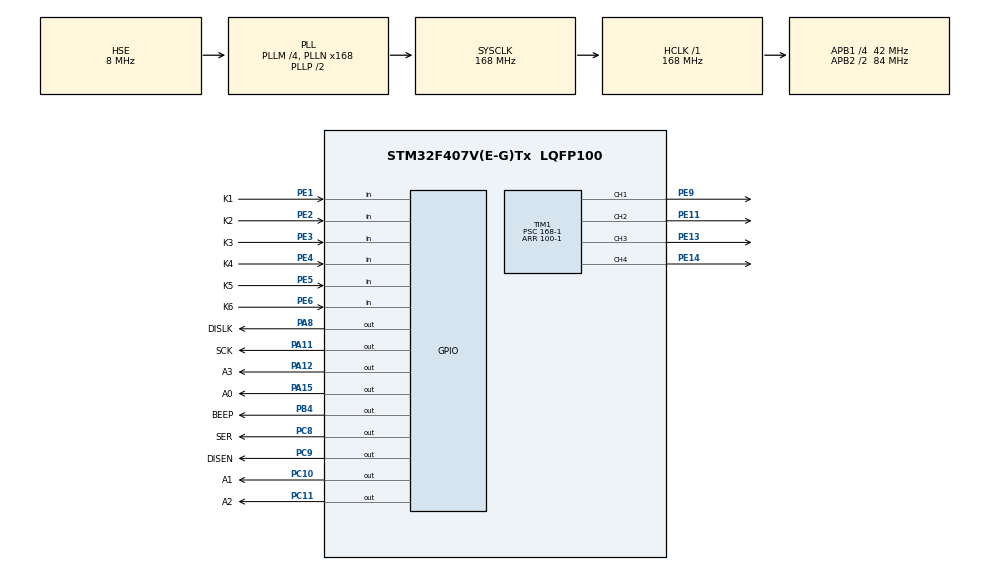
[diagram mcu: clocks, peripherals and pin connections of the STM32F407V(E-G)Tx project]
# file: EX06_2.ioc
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FREERTOS.Tasks01=TaskLED,24,256,StartTaskLED,Default,NULL,Dynamic,NULL,NULL;TaskBEEP,8,256,StartTaskBEEP,Default,NULL,Dynamic,NULL,NULL;TaskKEY,8,256,StartTaskKEY,Default,NULL,Dynamic,NULL,NULL;TaskSEG,8,128,StartTaskSEG,Default,NULL,Dynamic,NULL,NULL
Mcu.Family=STM32F4
Mcu.Name=STM32F407V(E-G)Tx
Mcu.Package=LQFP100
NVIC.PriorityGroup=NVIC_PRIORITYGROUP_4
NVIC.TIM1_BRK_TIM9_IRQn=true\:5\:0\:false\:false\:true\:true\:false\:true
NVIC.TIM4_IRQn=true\:5\:0\:false\:false\:true\:true\:true\:true
NVIC.TimeBase=TIM1_BRK_TIM9_IRQn
NVIC.TimeBaseIP=TIM9
PA11.GPIO_Label=SCK
PA11.Signal=GPIO_Output
PA12.GPIO_Label=A3
PA12.Signal=GPIO_Output
PA13.Mode=Serial_Wire
PA13.Signal=SYS_JTMS-SWDIO
PA14.Mode=Serial_Wire
PA14.Signal=SYS_JTCK-SWCLK
PA15.GPIO_Label=A0
PA15.Signal=GPIO_Output
PA8.GPIO_Label=DISLK
PA8.Signal=GPIO_Output
PB4.GPIO_Label=BEEP
PB4.Signal=GPIO_Output
PC10.GPIO_Label=A1
PC10.Signal=GPIO_Output
PC11.GPIO_Label=A2
PC11.Signal=GPIO_Output
PC8.GPIO_Label=SER
PC8.Signal=GPIO_Output
PC9.GPIO_Label=DISEN
PC9.Signal=GPIO_Output
PE1.GPIO_Label=K1
PE1.GPIO_PuPd=GPIO_PULLUP
PE1.Signal=GPIO_Input
PE11.Signal=S_TIM1_CH2
PE13.Signal=S_TIM1_CH3
PE14.Signal=S_TIM1_CH4
PE2.GPIO_Label=K2
PE2.GPIO_PuPd=GPIO_PULLUP
PE2.Signal=GPIO_Input
PE3.GPIO_Label=K3
PE3.GPIO_PuPd=GPIO_PULLUP
PE3.Signal=GPIO_Input
PE4.GPIO_Label=K4
PE4.GPIO_PuPd=GPIO_PULLUP
PE4.Signal=GPIO_Input
PE5.GPIO_Label=K5
PE5.GPIO_PuPd=GPIO_PULLDOWN
PE5.Signal=GPIO_Input
PE6.GPIO_Label=K6
PE6.GPIO_PuPd=GPIO_PULLDOWN
PE6.Signal=GPIO_Input
PE9.Signal=S_TIM1_CH1
PH0-OSC_IN.Mode=HSE-External-Oscillator
PH0-OSC_IN.Signal=RCC_OSC_IN
PH1-OSC_OUT.Mode=HSE-External-Oscillator
PH1-OSC_OUT.Signal=RCC_OSC_OUT
ProjectManager.HeapSize=0x200
ProjectManager.StackSize=0x400
ProjectManager.TargetToolchain=MDK-ARM V5.27
RCC.48MHZClocksFreq_Value=84000000
RCC.AHBFreq_Value=168000000
RCC.APB1CLKDivider=RCC_HCLK_DIV4
RCC.APB1Freq_Value=42000000
RCC.APB1TimFreq_Value=84000000
RCC.APB2CLKDivider=RCC_HCLK_DIV2
RCC.APB2Freq_Value=84000000
RCC.APB2TimFreq_Value=168000000
RCC.CortexFreq_Value=168000000
RCC.HCLKFreq_Value=168000000
RCC.HSE_VALUE=8000000
RCC.HSI_VALUE=16000000
RCC.LSE_VALUE=32768
RCC.PLLM=4
RCC.PLLN=168
RCC.PLLSourceVirtual=RCC_PLLSOURCE_HSE
RCC.SYSCLKFreq_VALUE=168000000
RCC.SYSCLKSource=RCC_SYSCLKSOURCE_PLLCLK
RCC.VCOOutputFreq_Value=336000000
SH.S_TIM1_CH1.0=TIM1_CH1,PWM Generation1 CH1
SH.S_TIM1_CH2.0=TIM1_CH2,PWM Generation2 CH2
SH.S_TIM1_CH3.0=TIM1_CH3,PWM Generation3 CH3
SH.S_TIM1_CH4.0=TIM1_CH4,PWM Generation4 CH4
TIM1.AutoReloadPreload=TIM_AUTORELOAD_PRELOAD_DISABLE
TIM1.Channel-PWM\ Generation1\ CH1=TIM_CHANNEL_1
TIM1.Channel-PWM\ Generation2\ CH2=TIM_CHANNEL_2
TIM1.Channel-PWM\ Generation3\ CH3=TIM_CHANNEL_3
TIM1.Channel-PWM\ Generation4\ CH4=TIM_CHANNEL_4
TIM1.OCIdleState_1=TIM_OCIDLESTATE_SET
TIM1.OCIdleState_2=TIM_OCIDLESTATE_SET
TIM1.OCIdleState_3=TIM_OCIDLESTATE_SET
TIM1.OCIdleState_4=TIM_OCIDLESTATE_SET
TIM1.OCPolarity_1=TIM_OCPOLARITY_LOW
TIM1.OCPolarity_2=TIM_OCPOLARITY_LOW
TIM1.OCPolarity_3=TIM_OCPOLARITY_LOW
TIM1.OCPolarity_4=TIM_OCPOLARITY_LOW
TIM1.Period=100-1
TIM1.Prescaler=168-1
TIM4.AutoReloadPreload=TIM_AUTORELOAD_PRELOAD_ENABLE
TIM4.Prescaler=168-1
VP_FREERTOS_VS_CMSIS_V2.Mode=CMSIS_V2
VP_SYS_VS_tim9.Mode=TIM9
VP_TIM1_VS_ClockSourceINT.Mode=Internal
VP_TIM4_VS_ClockSourceINT.Mode=Internal
board=custom

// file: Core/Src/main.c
/* USER CODE BEGIN Header */
/**
  ******************************************************************************
  * @file           : main.c
  * @brief          : Main program body
  ******************************************************************************
  * @attention
  *
  * <h2><center>&copy; Copyright (c) 2021 STMicroelectronics.
  * All rights reserved.</center></h2>
  *
  * This software component is licensed by ST under BSD 3-Clause license,
  * the "License"; You may not use this file except in compliance with the
  * License. You may obtain a copy of the License at:
  *                        opensource.org/licenses/BSD-3-Clause
  *
  ******************************************************************************
  */
/* USER CODE END Header */
#include "main.h"
#include "cmsis_os.h"
#include "tim.h"
#include "gpio.h"

/* USER CODE BEGIN PV */
int g_beep_time = 0;//Ĭ�ϲ���

/* USER CODE END PV */

void SystemClock_Config(void);
void MX_FREERTOS_Init(void);

int main(void)
{

  /* MCU Configuration--------------------------------------------------------*/

  /* Reset of all peripherals, Initializes the Flash interface and the Systick. */
  HAL_Init();

  /* Configure the system clock */
  SystemClock_Config();

  /* Initialize all configured peripherals */
  MX_GPIO_Init();
  MX_TIM4_Init();
  MX_TIM1_Init();

  /* Init scheduler */
  osKernelInitialize();  /* Call init function for freertos objects (in freertos.c) */
  MX_FREERTOS_Init();
  /* Start scheduler */
  osKernelStart();

  /* We should never get here as control is now taken by the scheduler */
  /* Infinite loop */
  while (1)
  {

  }
}

void SystemClock_Config(void)
{
  RCC_OscInitTypeDef RCC_OscInitStruct = {0};
  RCC_ClkInitTypeDef RCC_ClkInitStruct = {0};

  /** Configure the main internal regulator output voltage
  */
  __HAL_RCC_PWR_CLK_ENABLE();
  __HAL_PWR_VOLTAGESCALING_CONFIG(PWR_REGULATOR_VOLTAGE_SCALE1);
  /** Initializes the RCC Oscillators according to the specified parameters
  * in the RCC_OscInitTypeDef structure.
  */
  RCC_OscInitStruct.OscillatorType = RCC_OSCILLATORTYPE_HSE;
  RCC_OscInitStruct.HSEState = RCC_HSE_ON;
  RCC_OscInitStruct.PLL.PLLState = RCC_PLL_ON;
  RCC_OscInitStruct.PLL.PLLSource = RCC_PLLSOURCE_HSE;
  RCC_OscInitStruct.PLL.PLLM = 4;
  RCC_OscInitStruct.PLL.PLLN = 168;
  RCC_OscInitStruct.PLL.PLLP = RCC_PLLP_DIV2;
  RCC_OscInitStruct.PLL.PLLQ = 4;
  if (HAL_RCC_OscConfig(&RCC_OscInitStruct) != HAL_OK)
  {
    Error_Handler();
  }
  /** Initializes the CPU, AHB and APB buses clocks
  */
  RCC_ClkInitStruct.ClockType = RCC_CLOCKTYPE_HCLK|RCC_CLOCKTYPE_SYSCLK
                              |RCC_CLOCKTYPE_PCLK1|RCC_CLOCKTYPE_PCLK2;
  RCC_ClkInitStruct.SYSCLKSource = RCC_SYSCLKSOURCE_PLLCLK;
  RCC_ClkInitStruct.AHBCLKDivider = RCC_SYSCLK_DIV1;
  RCC_ClkInitStruct.APB1CLKDivider = RCC_HCLK_DIV4;
  RCC_ClkInitStruct.APB2CLKDivider = RCC_HCLK_DIV2;

  if (HAL_RCC_ClockConfig(&RCC_ClkInitStruct, FLASH_LATENCY_5) != HAL_OK)
  {
    Error_Handler();
  }
}

 /**
  * @brief  Period elapsed callback in non blocking mode
  * @note   This function is called  when TIM9 interrupt took place, inside
  * HAL_TIM_IRQHandler(). It makes a direct call to HAL_IncTick() to increment
  * a global variable "uwTick" used as application time base.
  * @param  htim : TIM handle
  * @retval None
  */
void HAL_TIM_PeriodElapsedCallback(TIM_HandleTypeDef *htim)
{
  /* USER CODE BEGIN Callback 0 */
	static uint8_t led_count=0;
  /* USER CODE END Callback 0 */
  if (htim->Instance == TIM9) {
    HAL_IncTick();
  }
  /* USER CODE BEGIN Callback 1 */
	if(htim->Instance == TIM4)
	{
		if(g_beep_time>0)
		{
			HAL_GPIO_TogglePin(BEEP_GPIO_Port,BEEP_Pin);
			--g_beep_time;
		}
	}

  /* USER CODE END Callback 1 */
}

void Error_Handler(void)
{
  __disable_irq();
  while (1)
  {
  }
}

/************************ (C) COPYRIGHT STMicroelectronics *****END OF FILE****/
